# STM32F730x register map
File version: 1.1
CPU: CM7 r0p1, little endian, MPU, FPU, 4 interrupt priority bits
Registers are 32-bit, read-write, reset 0x0 unless marked. A register's access mark holds for its fields unless they carry their own. Offsets are from the block's base; [hi:lo] are bit positions; {n}, {i} and the like mark numbered series.

## DBG — Debug support
Base 0xE0042000
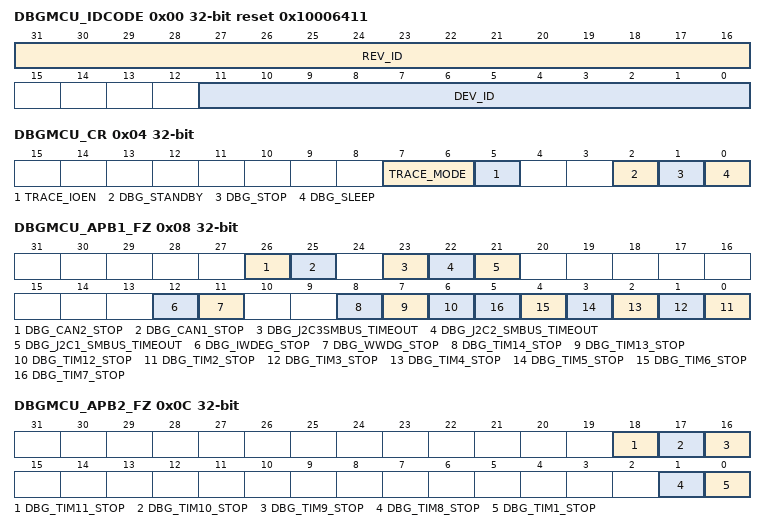
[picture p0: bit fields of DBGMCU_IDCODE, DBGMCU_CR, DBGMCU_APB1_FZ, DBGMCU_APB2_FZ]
0x00 DBGMCU_IDCODE ro reset 0x10006411 — IDCODE
  [31:16] REV_ID, [11:0] DEV_ID
0x04 DBGMCU_CR — Control Register
  [7:6] TRACE_MODE, [5] TRACE_IOEN, [2] DBG_STANDBY, [1] DBG_STOP, [0] DBG_SLEEP
0x08 DBGMCU_APB1_FZ — Debug MCU APB1 Freeze registe
  [26] DBG_CAN2_STOP, [25] DBG_CAN1_STOP, [23] DBG_J2C3SMBUS_TIMEOUT, [22] DBG_J2C2_SMBUS_TIMEOUT, [21] DBG_J2C1_SMBUS_TIMEOUT, [12] DBG_IWDEG_STOP, [11] DBG_WWDG_STOP, [8] DBG_TIM14_STOP, [7] DBG_TIM13_STOP, [6] DBG_TIM12_STOP, [n-2] DBG_TIM{n}_STOP (n=2..7)
0x0C DBGMCU_APB2_FZ — Debug MCU APB2 Freeze registe
  [18] DBG_TIM11_STOP — TIM11 counter stopped when core is halted
  [17] DBG_TIM10_STOP — TIM10 counter stopped when core is halted
  [16] DBG_TIM9_STOP — TIM9 counter stopped when core is halted
  [1] DBG_TIM8_STOP — TIM8 counter stopped when core is halted
  [0] DBG_TIM1_STOP — TIM1 counter stopped when core is halted

## DAC — Digital-to-analog converter
Base 0x40007400
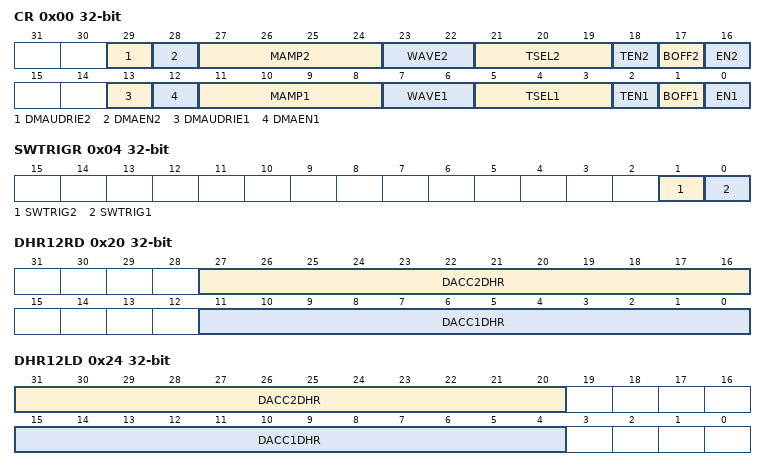
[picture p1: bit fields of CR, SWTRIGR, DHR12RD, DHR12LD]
0x00 CR — control register
  [29] DMAUDRIE2 — DAC channel2 DMA underrun interrupt enable
  [28] DMAEN2 — DAC channel2 DMA enable
  [27:24] MAMP2 — DAC channel2 mask/amplitude selector
  [23:22] WAVE2 — DAC channel2 noise/triangle wave generation enable
  [21:19] TSEL2 — DAC channel2 trigger selection
  [18] TEN2 — DAC channel2 trigger enable
  [17] BOFF2 — DAC channel2 output buffer disable
  [16] EN2 — DAC channel2 enable
  [13] DMAUDRIE1 — DAC channel1 DMA Underrun Interrupt enable
  [12] DMAEN1 — DAC channel1 DMA enable
  [11:8] MAMP1 — DAC channel1 mask/amplitude selector
  [7:6] WAVE1 — DAC channel1 noise/triangle wave generation enable
  [5:3] TSEL1 — DAC channel1 trigger selection
  [2] TEN1 — DAC channel1 trigger enable
  [1] BOFF1 — DAC channel1 output buffer disable
  [0] EN1 — DAC channel1 enable
0x04 SWTRIGR wo — software trigger register
  [1] SWTRIG2 — DAC channel2 software trigger
  [0] SWTRIG1 — DAC channel1 software trigger
0x08 DHR12R1 — channel1 12-bit right-aligned data holding register
  [11:0] DACC1DHR — DAC channel1 12-bit right-aligned data
0x0C DHR12L1 — channel1 12-bit left aligned data holding register
  [15:4] DACC1DHR — DAC channel1 12-bit left-aligned data
0x10 DHR8R1 — channel1 8-bit right aligned data holding register
  [7:0] DACC1DHR — DAC channel1 8-bit right-aligned data
0x14 DHR12R2 — channel2 12-bit right aligned data holding register
  [11:0] DACC2DHR — DAC channel2 12-bit right-aligned data
0x18 DHR12L2 — channel2 12-bit left aligned data holding register
  [15:4] DACC2DHR — DAC channel2 12-bit left-aligned data
0x1C DHR8R2 — channel2 8-bit right-aligned data holding register
  [7:0] DACC2DHR — DAC channel2 8-bit right-aligned data
0x20 DHR12RD — Dual DAC 12-bit right-aligned data holding register
  [27:16] DACC2DHR — DAC channel2 12-bit right-aligned data
  [11:0] DACC1DHR — DAC channel1 12-bit right-aligned data
0x24 DHR12LD — DUAL DAC 12-bit left aligned data holding register
  [31:20] DACC2DHR — DAC channel2 12-bit left-aligned data
  [15:4] DACC1DHR — DAC channel1 12-bit left-aligned data
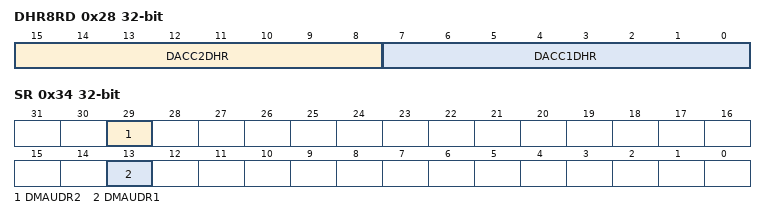
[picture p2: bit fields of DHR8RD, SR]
0x28 DHR8RD — DUAL DAC 8-bit right aligned data holding register
  [15:8] DACC2DHR — DAC channel2 8-bit right-aligned data
  [7:0] DACC1DHR — DAC channel1 8-bit right-aligned data
0x2C DOR1 ro — channel1 data output register
  [11:0] DACC1DOR — DAC channel1 data output
0x30 DOR2 ro — channel2 data output register
  [11:0] DACC2DOR — DAC channel2 data output
0x34 SR — status register
  [29] DMAUDR2 — DAC channel2 DMA underrun flag
  [13] DMAUDR1 — DAC channel1 DMA underrun flag

## EXTI — External interrupt/event controller
Base 0x40013C00
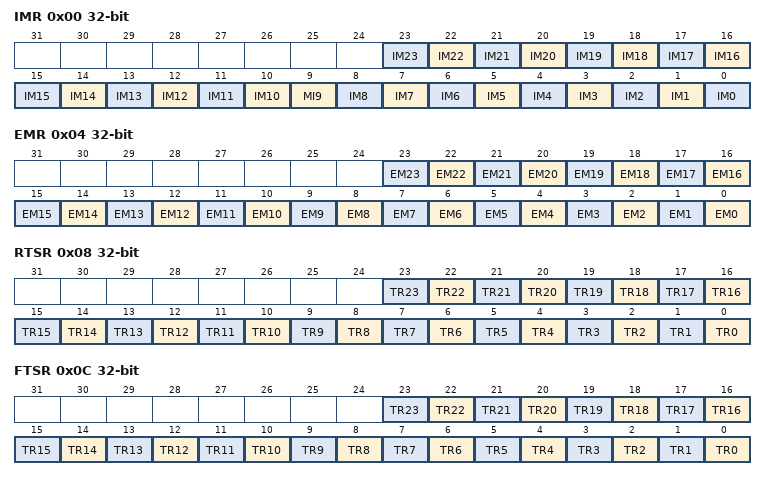
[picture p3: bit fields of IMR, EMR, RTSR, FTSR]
0x00 IMR — Interrupt mask register (EXTI_IMR)
  [n] IM{n} (n=10..23) — Interrupt Mask on line {n}
  [9] MI9 — Interrupt Mask on line 9
  [n] IM{n} (n=0..8) — Interrupt Mask on line {n}
0x04 EMR — Event mask register (EXTI_EMR)
  [n] EM{n} (n=0..23) — Event Mask on line {n}
0x08 RTSR — Rising Trigger selection register (EXTI_RTSR)
  [n] TR{n} (n=0..23) — Rising trigger event configuration of line {n}
0x0C FTSR — Falling Trigger selection register (EXTI_FTSR)
  [n] TR{n} (n=0..23) — Falling trigger event configuration of line {n}
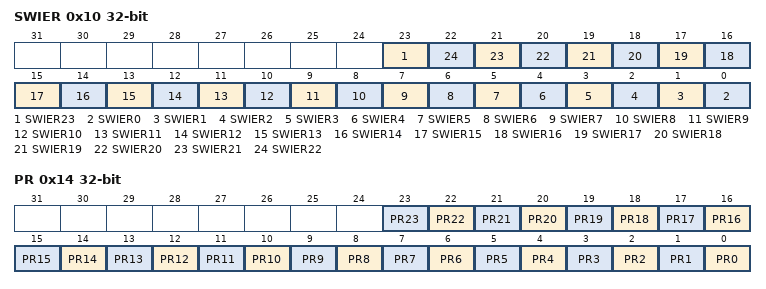
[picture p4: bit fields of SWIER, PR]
0x10 SWIER — Software interrupt event register (EXTI_SWIER)
  [23] SWIER23 — Software Interrupt on line 22
  [n] SWIER{n} (n=0..22) — Software Interrupt on line {n}
0x14 PR — Pending register (EXTI_PR)
  [n] PR{n} (n=0..23) — Pending bit {n}
